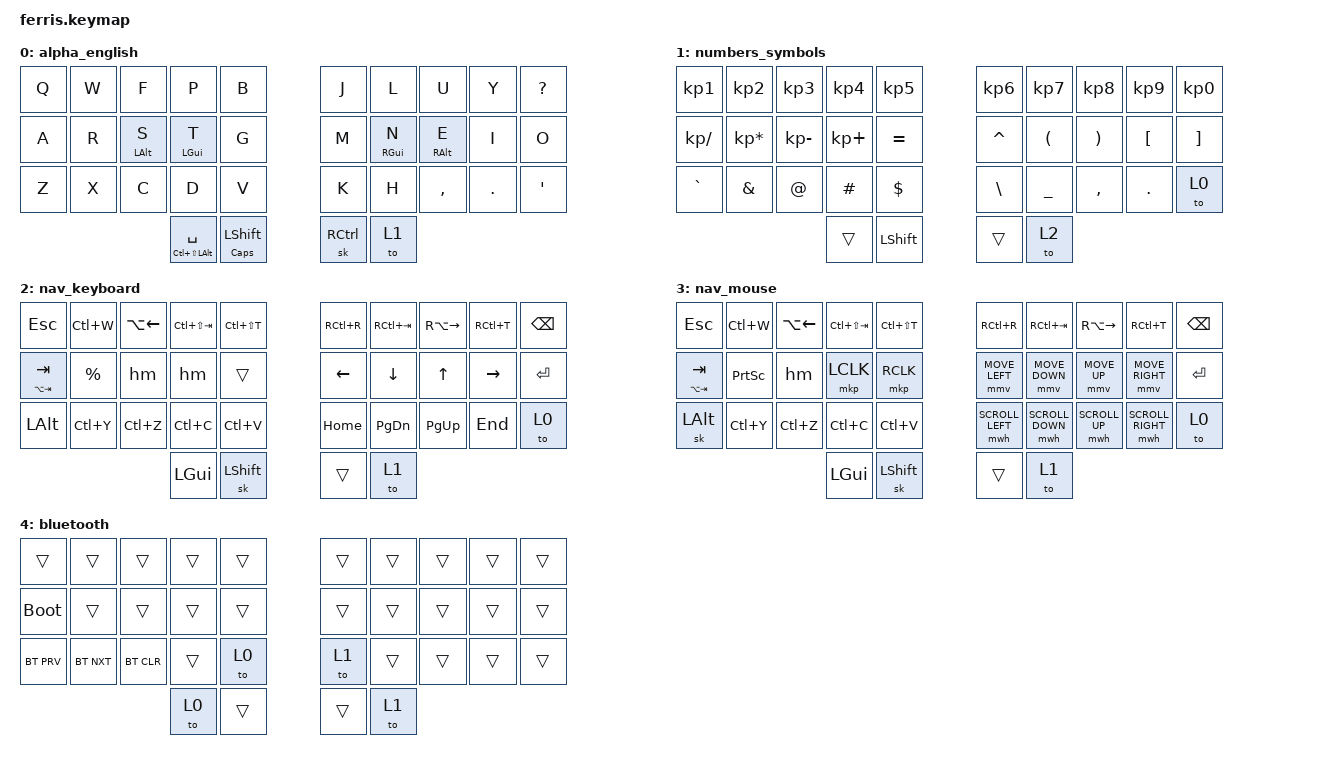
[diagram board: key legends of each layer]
/*
 * Copyright (c) 2020 The ZMK Contributors
 *
 * SPDX-License-Identifier: MIT
 */

#include <behaviors.dtsi>
#include <dt-bindings/zmk/keys.h>
#include <dt-bindings/zmk/bt.h>
#include <dt-bindings/zmk/mouse.h>
// #include "keys_heb.h"

&mt {
    tapping_term_ms = <200>;
    flavor = "tap-preferred";
};
&sk {
     release-after-ms = <2000>;
     quick-release;
 };

// Layers
#define ALPHA   0
// #define HEBREW  1
#define SYMBOLS 1
#define KBNAV   2
#define MSNAV   3	
#define BLTH    4

/* 34 Key Matrix
╭──────────────╮ ╭──────────────╮
│ 0  1  2  3  4│ │ 5  6  7  8  9│
│10 11 12 13 14│ │15 16 17 18 19│
│20 21 22 23 24│ │25 26 27 28 29│
╰────────╮30 31│ │32 33╭────────╯
         ╰─────╯ ╰─────╯         
*/

/ {
    combos {
        compatible = "zmk,combos";

// General combos
        combo_to_alpha {
            timeout-ms = <50>;
            key-positions = <30 33>; // Inner thumb keys
            bindings = <&to ALPHA>;
        };

// Multi-Layer combos
        combo_return {
            timeout-ms = <50>;
            key-positions = <18 19>; // Middle-rightmost keys
            bindings = <&kp RETURN>;
            layers = <ALPHA SYMBOLS>;
        };

        combo_escape {
            timeout-ms = <50>;
            key-positions = <0 1>; // Top-leftmost corner keys
            bindings = <&kp ESCAPE>;
            layers = <ALPHA SYMBOLS>;
        };

        combo_backspace {
            timeout-ms = <50>;
            key-positions = <8 9>; // Top-rightmost corner keys
            bindings = <&kp BACKSPACE>;
            layers = <ALPHA SYMBOLS>;
        };

        combo_tab {
            timeout-ms = <50>;
            key-positions = <10 11>; // Middle-leftmost keys
            bindings = <&kp TAB>;
            layers = <ALPHA SYMBOLS>;
        };

        combo_caps_word {
            timeout-ms = <50>;
            key-positions = <24 25>; // Bottom inner keys
            bindings = <&caps_word>;
            layers = <ALPHA SYMBOLS>;
        };

// Alpha layer combos
        combo_exclamation_point {
            timeout-ms = <50>;
            key-positions = <31 9>; // Shift + Question mark
            bindings = <&kp EXCLAMATION>;
            layers = <ALPHA>;
        };

        combo_underscore {
            timeout-ms = <50>;
            key-positions = <21 22>;
            bindings = <&kp UNDERSCORE>;
            layers = <ALPHA>;
        };
    };

    behaviors {
        hm: homerow_mods {
            compatible = "zmk,behavior-hold-tap";
            label = "HOMEROW_MODS";
            #binding-cells = <2>;
            tapping-term-ms = <200>;
            quick_tap_ms = <0>;
            flavor = "tap-preferred";
            bindings =
                <&kp>,
                <&kp>;
        };
        hs: homerow_shifts {
            compatible = "zmk,behavior-hold-tap";
            label = "HOMEROW_SHIFTS";
            #binding-cells = <2>;
            tapping-term-ms = <150>;
            quick_tap_ms = <0>;
            flavor = "balanced";
            bindings =
                <&kp>,
                <&kp>;
        };
        hsl: homerow_shifts_layer {
            compatible = "zmk,behavior-hold-tap";
            label = "HOMEROW_SHIFTS_LAYER";
            #binding-cells = <2>;
            tapping-term-ms = <150>;
            quick_tap_ms = <0>;
            flavor = "balanced";
            bindings =
                <&kp>,
                <&to>;
        };
        td: tapdance {
            compatible = "zmk,behavior-hold-tap";
            label = "TAPDANCE";
            #binding-cells = <2>;
            tapping-term-ms = <150>;
            quick_tap_ms = <0>;
            flavor = "tap-preferred";
            bindings =
                <&kp>,
                <&kp>;
        };
        bl: layertap {
            compatible = "zmk,behavior-hold-tap";
            label = "LAYERTAP";
            #binding-cells = <2>;
            tapping-term-ms = <150>;
            quick_tap_ms = <0>;
            flavor = "tap-preferred";
            bindings =
                <&to>,
                <&kp>;
        };
    };


    keymap {
        compatible = "zmk,keymap";

        alpha_english {
/* English Alphas
---------------------------------------------------------------------------------------------------------------------
|    Q    |    W    |    F    |    P    |    B    |          |    J    |    L    |    U    |    Y    | ? (+:!) |
|    A    |    R    |    S    |    T    |    G    |          |    M    |    N    |    E    |    I    |    O    |
|    Z    |    X    |    C    |    D    |    V    |          |    K    |    H    |, (+: ;) |. (+: :) |' (+: ") |
          |   SPACE (h:MEH)   |   SHIFT (h:CAPS)  |          |       CTRL        | L2 (+:L3) (h:L4)  |
---------------------------------------------------------------------------------------------------------------------
*/
            bindings = <
&kp Q   &kp W   &kp F       &kp P       &kp B               &kp J   &kp L       &kp U       &kp Y   &kp QMARK
&kp A   &kp R   &hm LALT S  &hm LGUI T  &kp G               &kp M   &hm RGUI N  &hm RALT E  &kp I   &kp O
&kp Z   &kp X   &kp C       &kp D       &kp V               &kp K   &kp H       &kp COMMA   &kp DOT &kp SQT
                &mt LC(LS(LALT)) SPACE  &mt CAPS LSHIFT     &sk RCTRL   &to 1
            >;
        };

//         alpha_hebrew {
// /* Hebrew Alphas
// ---------------------------------------------------------------------------------------------------------------------
// |   QOF   |   RESH  |   ALEF  |   TET   |   VAV   |          |  F_NUN  |MEM (+:F_MEM)|   PEH   | F_TSADI | ? (+:!) |
// |   SHIN  |  DALET  |  GIMEL  |   KAF   |   AYIN  |          |   YOD   |   HET       |  LAMED  |  F_KAF  |  F_PEH  |
// |  ZAYIN  |  SAMEKH |   BET   |    HE   |   NUN   |          |  TSADI  |   TAV       | , (+: ;)| . (+: :)| ' (+: ")|
//           |   SPACE (h:MEH)   |   SHIFT (h:CAPS)  |          |       CTRL            | L2 (+:L3) (h:L4)  |
// ---------------------------------------------------------------------------------------------------------------------
// */
//             bindings = <
// &kp HEB_QOF  &kp HEB_RESH &kp HEB_ALEF         &kp HEB_TET      &kp HEB_VAV          &kp HEB_FNUN &kp HEB_MEM      &kp HEB_PE           &kp HEB_FTSDI    &kp HEB_QMARK
// &kp HEB_SHIN &kp HEB_DALT &hm LALT HEB_GIML    &hm LGUI HEB_KAF &kp HEB_AYIN         &kp HEB_YOD  &hm RGUI HEB_HET &hm RALT HEB_LAMD    &kp HEB_FKAF     &kp HEB_FPE
// &kp HEB_ZAYN &kp HEB_SMKH &kp HEB_BET          &kp HEB_HE       &kp HEB_NUN          &kp HEB_TSDI &kp HEB_TAV      &kp HEB_COMMA        &kp HEB_DOT      &kp HEB_SQT
//                                             &trans          &trans              &trans      &trans
//             >;
//         };

        numbers_symbols {
/* Numbers and Symbols 
---------------------------------------------------------------------------------------------------------------------
|    1    |    2    |    3    |    4    |    5    |          |    6    |    7    |    8    |    9    |    0    |
|    /    |    *    |    -    |    +    |    =    |          | ^ (+: %)| ( (+: <)| ) (+: >)| [ (+: {)| ] (+: })|
| ` (+: ~)|    7    |    8    |    9    | $ (+: ₪)|          | \ (+: |)|    _    | , (+: ;)| . (+: :)|  TO L0  |
          |   SPACE (h:MEH)   |   SHIFT (h:FN)    |          |       CTRL        |   L2     (+:L3)   |
---------------------------------------------------------------------------------------------------------------------
*/
            bindings = <
&kp KP_N1    &kp KP_N2       &kp KP_N3    &kp KP_N4   &kp KP_N5       &kp KP_N6     &kp KP_N7 &kp KP_N8   &kp KP_N9 &kp KP_N0
&kp KP_SLASH &kp KP_MULTIPLY &kp KP_MINUS &kp KP_PLUS &kp EQUAL       &kp CARET     &kp LPAR  &kp RPAR    &kp LBKT  &kp RBKT
&kp GRAVE    &kp AMPERSAND   &kp AT_SIGN  &kp HASH    &kp DOLLAR      &kp BACKSLASH &kp UNDER &kp COMMA   &kp DOT   &to 0
                                          &trans      &kp LSHIFT      &trans        &to 2
            >;
        };

        nav_keyboard {
/* Keyboard Navigation
----------------------------------------------------------------------------------------------------------------------------
|   ESC        | EXIT TAB | PREV PAGE | PREV TAB | REOP TAB |         | REFRESH | NEXT TAB | NEXT PAGE | NEW TAB |  BSPACE |
| TAB (h:alt+) |          |           |          |          |         | LARROW  | DARROW   | UARROW    | RARROW  |  ENTER  |
|    ALT       |   REDO   |    UNDO   |   COPY   |   PASTE  |         |  HOME   |  PG DN   |  PG UP    |   END   |  TO L0  |
          |   SPACE (h:MEH)   |   SHIFT (h:FN)    |          |       CTRL        |   L2     (+:L3)   |
----------------------------------------------------------------------------------------------------------------------------
*/
            bindings = <
&kp ESC         &kp LC(W) &kp LA(LEFT)    &kp LC(LS(TAB)) &kp LC(LS(T)) &kp RC(R) &kp RC(TAB) &kp RA(RIGHT)   &kp RC(T)   &kp BSPC
&mt LA(TAB) TAB &kp PRCNT &hm             &hm             &trans        &kp LEFT  &kp DOWN    &kp UP          &kp RIGHT   &kp RET
&kp LALT        &kp LC(Y) &kp LC(Z)       &kp LC(C)       &kp LC(V)     &kp HOME  &kp PG_DN   &kp PG_UP       &kp END     &to 0
                                          &kp LGUI        &sk LSHIFT    &trans &to 1
            >;
        };

        nav_mouse {
/* Mouse Navigation
----------------------------------------------------------------------------------------------------------------------------
|   ESC        | EXIT TAB | PREV PAGE | PREV TAB | REOP TAB |         | REFRESH | NEXT TAB | NEXT PAGE | NEW TAB |  BSPACE |
| TAB (h:alt+) |          |           |          |          |         | LMOUSE  | DMOUSE   | UMOUSE    | RMOUSE  |  ENTER  |
|    ALT       |   REDO   |    UNDO   |   COPY   |   PASTE  |         |  HOME   |  PG DN   |  PG UP    |   END   |  TO L0  |
          |   SPACE (h:MEH)   |   SHIFT (h:FN)    |          |       CTRL        |   L2     (+:L3)   |
----------------------------------------------------------------------------------------------------------------------------
*/
            bindings = <
&kp ESC         &kp LC(W) &kp LA(LEFT) &kp LC(LS(TAB)) &kp LC(LS(T)) &kp RC(R)        &kp RC(TAB)      &kp RA(RIGHT)  &kp RC(T)         &kp BSPC
&mt LA(TAB) TAB &kp PSCRN &hm          &mkp LCLK       &mkp RCLK     &mmv MOVE_LEFT   &mmv MOVE_DOWN   &mmv MOVE_UP   &mmv MOVE_RIGHT   &kp RET
&sk LALT        &kp LC(Y) &kp LC(Z)    &kp LC(C)       &kp LC(V)     &mwh SCROLL_LEFT &mwh SCROLL_DOWN &mwh SCROLL_UP &mwh SCROLL_RIGHT &to 0
                                       &kp LGUI        &sk LSHIFT    &trans        &to 1
            >;
        };

        bluetooth {
// Bluetooth
            bindings = <
      &trans      &trans      &trans  &trans  &trans  &trans  &trans  &trans  &trans  &trans
 &bootloader      &trans      &trans  &trans  &trans  &trans  &trans  &trans  &trans  &trans
  &bt BT_PRV  &bt BT_NXT  &bt BT_CLR  &trans   &to 0   &to 1  &trans  &trans  &trans  &trans
                                       &to 0  &trans  &trans   &to 1
            >;
        };
    };
};
